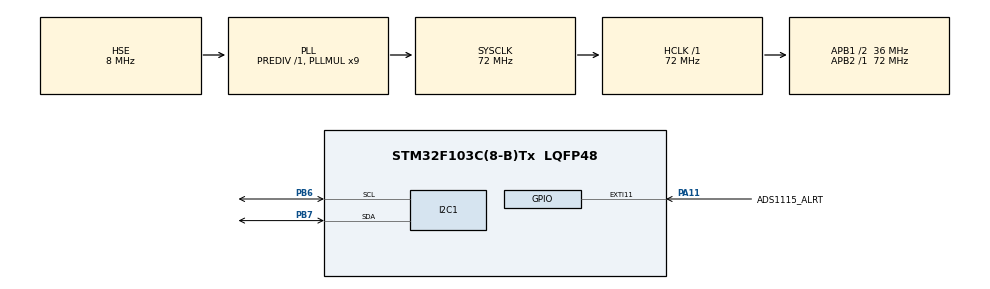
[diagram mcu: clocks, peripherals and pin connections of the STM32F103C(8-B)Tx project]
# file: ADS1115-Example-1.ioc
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I2C1.I2C_Mode=I2C_Fast
Mcu.Family=STM32F1
Mcu.Name=STM32F103C(8-B)Tx
Mcu.Package=LQFP48
NVIC.EXTI15_10_IRQn=true\:0\:0\:false\:false\:true\:true\:true\:true
NVIC.PriorityGroup=NVIC_PRIORITYGROUP_4
PA11.GPIO_Label=ADS1115_ALRT
PA11.GPIO_ModeDefaultEXTI=GPIO_MODE_IT_FALLING
PA11.Signal=GPXTI11
PA13.Mode=Serial_Wire
PA13.Signal=SYS_JTMS-SWDIO
PA14.Mode=Serial_Wire
PA14.Signal=SYS_JTCK-SWCLK
PB6.Mode=I2C
PB6.Signal=I2C1_SCL
PB7.Mode=I2C
PB7.Signal=I2C1_SDA
PD0-OSC_IN.Mode=HSE-External-Oscillator
PD0-OSC_IN.Signal=RCC_OSC_IN
PD1-OSC_OUT.Mode=HSE-External-Oscillator
PD1-OSC_OUT.Signal=RCC_OSC_OUT
ProjectManager.HeapSize=0x200
ProjectManager.StackSize=0x400
ProjectManager.TargetToolchain=STM32CubeIDE
RCC.AHBFreq_Value=72000000
RCC.APB1CLKDivider=RCC_HCLK_DIV2
RCC.APB1Freq_Value=36000000
RCC.APB1TimFreq_Value=72000000
RCC.APB2Freq_Value=72000000
RCC.APB2TimFreq_Value=72000000
RCC.HCLKFreq_Value=72000000
RCC.PLLMUL=RCC_PLL_MUL9
RCC.PLLSourceVirtual=RCC_PLLSOURCE_HSE
RCC.SYSCLKFreq_VALUE=72000000
RCC.SYSCLKSource=RCC_SYSCLKSOURCE_PLLCLK
RCC.USBFreq_Value=72000000
board=custom

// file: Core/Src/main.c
/* USER CODE BEGIN Header */
/**
  ******************************************************************************
  * @file           : main.c
  * @brief          : Main program body
  ******************************************************************************
  * @attention
  *
  * Copyright (c) 2024 STMicroelectronics.
  * All rights reserved.
  *
  * This software is licensed under terms that can be found in the LICENSE file
  * in the root directory of this software component.
  * If no LICENSE file comes with this software, it is provided AS-IS.
  *
  ******************************************************************************
  */
/* USER CODE END Header */
#include "main.h"

/* USER CODE BEGIN Includes */
#include <stddef.h>

#include "driver_ads1115.h"
#include "driver_ads1115_interface.h"
/* USER CODE END Includes */

/* USER CODE BEGIN PTD */
typedef struct{
	int16_t Raw;
	float Value;
	uint8_t Rdy;
	uint16_t SPS;
}Alrt_ADS_t;
/* USER CODE END PTD */

I2C_HandleTypeDef hi2c1;

/* USER CODE BEGIN PV */
ads1115_handle_t Ads1115;
uint16_t Alrt_Rdy_Cnt;
Alrt_ADS_t AlrtData;
/* USER CODE END PV */

void SystemClock_Config(void);
static void MX_GPIO_Init(void);
static void MX_I2C1_Init(void);

/* USER CODE BEGIN 0 */

/*
 * Callbacks
 */

void HAL_GPIO_EXTI_Callback(uint16_t GPIO_Pin){
	if (GPIO_Pin == ADS1115_ALRT_Pin){
		AlrtData.Rdy = 1;
		Alrt_Rdy_Cnt++;
	}
}

/*
 * Initialize
 */
void _init_ads1115(ads1115_handle_t *Handle, uint8_t isRdy){
	/* Inicializa o Handle do ADS115 e atribui as funcoes */
	DRIVER_ADS1115_LINK_INIT(Handle, ads1115_handle_t);
	// Funcao de inicializacao da I2C
	DRIVER_ADS1115_LINK_IIC_INIT(Handle, ads1115_interface_iic_init);
	// Funcao de deinicializacao do I2C
	DRIVER_ADS1115_LINK_IIC_DEINIT(Handle, ads1115_interface_iic_deinit);
	// Funcao para leitura de registradores do ADS1115
    DRIVER_ADS1115_LINK_IIC_READ(Handle, ads1115_interface_iic_read);
    // Funcao para escrever em registradores do ADS1115
    DRIVER_ADS1115_LINK_IIC_WRITE(Handle, ads1115_interface_iic_write);
    // Funcao de Delay, em millisegundos
    DRIVER_ADS1115_LINK_DELAY_MS(Handle, ads1115_interface_delay_ms);
    // Funcao para geracao de Logs do driver
    DRIVER_ADS1115_LINK_DEBUG_PRINT(Handle, ads1115_interface_debug_print);

    /* Configura o driver do ADS1115 em Modo Alert ou Ready */

    // Alert Mode
    if (isRdy == 0){
    	int16_t HighT, LowT;
        // Atribui o Endereço de acordo com o sinal no terminal de ADDR, neste caso, GND
        ads1115_set_addr_pin(Handle, ADS1115_ADDR_GND);
        // Iniciliza o chip do ADS1115
        ads1115_init(Handle);
        // Define o canal do MUX para AIN0 como V+ e GND como V- (Vin = AIN0-GND)
        ads1115_set_channel(Handle, ADS1115_CHANNEL_AIN0_GND);
        // Define o range do PGA para a tensao de +-4.096V
        ads1115_set_range(Handle, ADS1115_RANGE_4P096V);
        // Define a velocidade de leitura máxima, de 860 Samples per Second
        ads1115_set_rate(Handle, ADS1115_RATE_860SPS);

        ads1115_set_compare_mode(Handle, ADS1115_COMPARE_WINDOW);
        ads1115_set_comparator_queue(Handle, ADS1115_COMPARATOR_QUEUE_4_CONV);

        ads1115_convert_to_register(Handle, 1.5, &LowT);
        ads1115_convert_to_register(Handle, 1.8, &HighT);
        ads1115_set_compare_threshold(Handle, HighT, LowT);
        // Desabilita o comparador
        ads1115_set_compare(Handle, ADS1115_BOOL_TRUE);

        // Inicia a conversao continua do ADS1115
        ads1115_start_continuous_read(Handle);
    }
    // Ready Mode
    else{
        // Atribui o Endereço de acordo com o sinal no terminal de ADDR, neste caso, GND
        ads1115_set_addr_pin(Handle, ADS1115_ADDR_GND);
        // Iniciliza o chip do ADS1115
        ads1115_init(Handle);
        // Define o canal do MUX para AIN0 como V+ e GND como V- (Vin = AIN0-GND)
        ads1115_set_channel(Handle, ADS1115_CHANNEL_AIN0_GND);
        // Define o range do PGA para a tensao de +-4.096V
        ads1115_set_range(Handle, ADS1115_RANGE_4P096V);
        // Define a velocidade de leitura máxima, de 860 Samples per Second
        ads1115_set_rate(Handle, ADS1115_RATE_860SPS);

        ads1115_set_comparator_queue(Handle, ADS1115_COMPARATOR_QUEUE_1_CONV);
        ads1115_set_compare_threshold(Handle, 0x8000, 0x7FFF);
        // Desabilita o comparador
        ads1115_set_compare(Handle, ADS1115_BOOL_TRUE);

        // Inicia a conversao continua do ADS1115
        ads1115_start_continuous_read(Handle);
    }
}

/* USER CODE END 0 */

int main(void)
{
  /* USER CODE BEGIN 1 */
	uint32_t Tick1000;
  /* USER CODE END 1 */

  /* MCU Configuration--------------------------------------------------------*/

  /* Reset of all peripherals, Initializes the Flash interface and the Systick. */
  HAL_Init();

  /* Configure the system clock */
  SystemClock_Config();

  /* Initialize all configured peripherals */
  MX_GPIO_Init();
  MX_I2C1_Init();
  /* USER CODE BEGIN 2 */
  _init_ads1115(&Ads1115, 1);
  /* USER CODE END 2 */

  /* Infinite loop */
  /* USER CODE BEGIN WHILE */
  Tick1000 = HAL_GetTick();
  AlrtData.Rdy = 0;
  AlrtData.SPS = 0;
  while (1)
  {
	  if (AlrtData.Rdy == 1){
		  AlrtData.Rdy = 0;
		  ads1115_continuous_read(&Ads1115, &AlrtData.Raw, &AlrtData.Value);
	  }
	  if ((HAL_GetTick() - Tick1000) >= 1000){
		  Tick1000 = HAL_GetTick();
		  AlrtData.SPS = Alrt_Rdy_Cnt;
		  Alrt_Rdy_Cnt = 0;
	  }
    /* USER CODE END WHILE */

  }
}

void SystemClock_Config(void)
{
  RCC_OscInitTypeDef RCC_OscInitStruct = {0};
  RCC_ClkInitTypeDef RCC_ClkInitStruct = {0};

  /** Initializes the RCC Oscillators according to the specified parameters
  * in the RCC_OscInitTypeDef structure.
  */
  RCC_OscInitStruct.OscillatorType = RCC_OSCILLATORTYPE_HSE;
  RCC_OscInitStruct.HSEState = RCC_HSE_ON;
  RCC_OscInitStruct.HSEPredivValue = RCC_HSE_PREDIV_DIV1;
  RCC_OscInitStruct.HSIState = RCC_HSI_ON;
  RCC_OscInitStruct.PLL.PLLState = RCC_PLL_ON;
  RCC_OscInitStruct.PLL.PLLSource = RCC_PLLSOURCE_HSE;
  RCC_OscInitStruct.PLL.PLLMUL = RCC_PLL_MUL9;
  if (HAL_RCC_OscConfig(&RCC_OscInitStruct) != HAL_OK)
  {
    Error_Handler();
  }

  /** Initializes the CPU, AHB and APB buses clocks
  */
  RCC_ClkInitStruct.ClockType = RCC_CLOCKTYPE_HCLK|RCC_CLOCKTYPE_SYSCLK
                              |RCC_CLOCKTYPE_PCLK1|RCC_CLOCKTYPE_PCLK2;
  RCC_ClkInitStruct.SYSCLKSource = RCC_SYSCLKSOURCE_PLLCLK;
  RCC_ClkInitStruct.AHBCLKDivider = RCC_SYSCLK_DIV1;
  RCC_ClkInitStruct.APB1CLKDivider = RCC_HCLK_DIV2;
  RCC_ClkInitStruct.APB2CLKDivider = RCC_HCLK_DIV1;

  if (HAL_RCC_ClockConfig(&RCC_ClkInitStruct, FLASH_LATENCY_2) != HAL_OK)
  {
    Error_Handler();
  }
}

static void MX_I2C1_Init(void)
{

  hi2c1.Instance = I2C1;
  hi2c1.Init.ClockSpeed = 400000;
  hi2c1.Init.DutyCycle = I2C_DUTYCYCLE_2;
  hi2c1.Init.OwnAddress1 = 0;
  hi2c1.Init.AddressingMode = I2C_ADDRESSINGMODE_7BIT;
  hi2c1.Init.DualAddressMode = I2C_DUALADDRESS_DISABLE;
  hi2c1.Init.OwnAddress2 = 0;
  hi2c1.Init.GeneralCallMode = I2C_GENERALCALL_DISABLE;
  hi2c1.Init.NoStretchMode = I2C_NOSTRETCH_DISABLE;
  if (HAL_I2C_Init(&hi2c1) != HAL_OK)
  {
    Error_Handler();
  }

}

static void MX_GPIO_Init(void)
{
  GPIO_InitTypeDef GPIO_InitStruct = {0};

  /* GPIO Ports Clock Enable */
  __HAL_RCC_GPIOD_CLK_ENABLE();
  __HAL_RCC_GPIOA_CLK_ENABLE();
  __HAL_RCC_GPIOB_CLK_ENABLE();

  /*Configure GPIO pin : ADS1115_ALRT_Pin */
  GPIO_InitStruct.Pin = ADS1115_ALRT_Pin;
  GPIO_InitStruct.Mode = GPIO_MODE_IT_FALLING;
  GPIO_InitStruct.Pull = GPIO_NOPULL;
  HAL_GPIO_Init(ADS1115_ALRT_GPIO_Port, &GPIO_InitStruct);

  /* EXTI interrupt init*/
  HAL_NVIC_SetPriority(EXTI15_10_IRQn, 0, 0);
  HAL_NVIC_EnableIRQ(EXTI15_10_IRQn);

}

void Error_Handler(void)
{
  __disable_irq();
  while (1)
  {
  }
}
